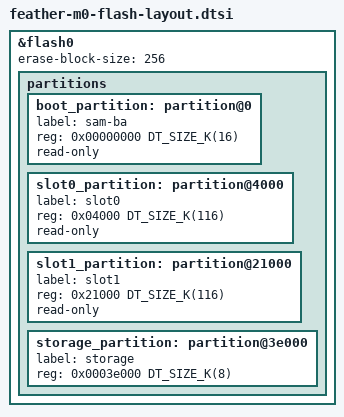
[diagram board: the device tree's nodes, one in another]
&flash0 {
	/* Write size set to 4 in samd2x.dtsi but TRM seems to indicate a write page size of 64 B */
	/* write-block-size = <64>; */
	erase-block-size = <256>;

	partitions {
		boot_partition: partition@0 {
			label = "sam-ba";
			reg = <0x00000000 DT_SIZE_K(16)>;
			read-only;
		};

		slot0_partition: partition@4000 {
			label = "slot0";
			reg = <0x04000 DT_SIZE_K(116)>;
			read-only;
		};

		slot1_partition: partition@21000 {
			label = "slot1";
			reg = <0x21000 DT_SIZE_K(116)>;
			read-only;
		};

		storage_partition: partition@3e000 {
			label = "storage";
			reg = <0x0003e000 DT_SIZE_K(8)>;
		};
	};
};
